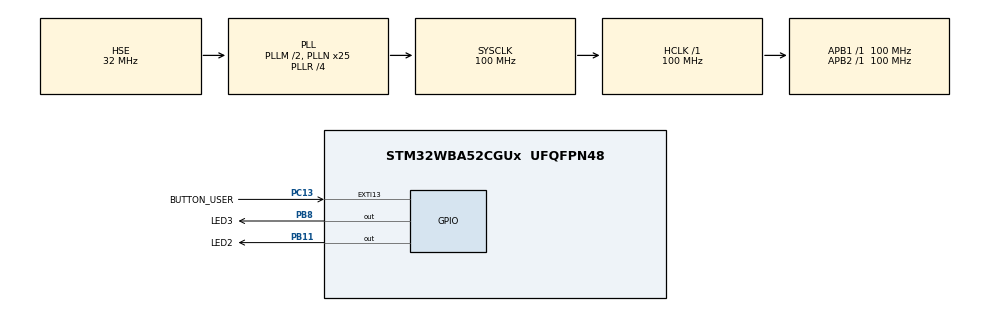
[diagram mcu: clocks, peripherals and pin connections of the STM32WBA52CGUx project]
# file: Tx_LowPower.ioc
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CORTEX_M33_NS.userName=CORTEX_M33
Mcu.Family=STM32WBA
Mcu.Name=STM32WBA52CGUx
Mcu.Package=UFQFPN48
NVIC.EXTI13_IRQn=true\:0\:0\:true\:false\:true\:false\:true\:true\:true
NVIC.PriorityGroup=NVIC_PRIORITYGROUP_4
NVIC.TIM16_IRQn=true\:15\:0\:false\:false\:true\:false\:false\:true\:true
NVIC.TimeBase=TIM16_IRQn
NVIC.TimeBaseIP=TIM16
OSC_IN.Mode=HSE-External-Oscillator
OSC_IN.Signal=RCC_OSC_IN
OSC_OUT.Mode=HSE-External-Oscillator
OSC_OUT.Signal=RCC_OSC_OUT
PB11.GPIO_Label=LED2
PB11.PinState=GPIO_PIN_SET
PB11.Signal=GPIO_Output
PB8.GPIO_Label=LED3
PB8.PinState=GPIO_PIN_SET
PB8.Signal=GPIO_Output
PC13.GPIO_Label=BUTTON_USER
PC13.GPIO_ModeDefaultEXTI=GPIO_MODE_IT_FALLING
PC13.GPIO_PuPd=GPIO_PULLUP
PC13.Signal=GPXTI13
PWR.pwrPrivilege=PWR_PRIVILEGE_NO
ProjectManager.HeapSize=0x200
ProjectManager.StackSize=0x400
ProjectManager.TargetToolchain=EWARM V9.20
RCC.ADCFreq_Value=100000000
RCC.AHB5CLKDivider=DIV4
RCC.AHBFreq_Value=100000000
RCC.APB1Freq_Value=100000000
RCC.APB1TimFreq_Value=100000000
RCC.APB2Freq_Value=100000000
RCC.APB2TimFreq_Value=100000000
RCC.CortexFreq_Value=12500000
RCC.HCLKFreq_Value=100000000
RCC.HSE_VALUE=32000000
RCC.HSI_VALUE=16000000
RCC.LSE_VALUE=32768
RCC.PLL1R=4
RCC.PLLFRACN=0
RCC.PLLM=2
RCC.PLLN=25
RCC.PLLSourceVirtual=RCC_PLLSOURCE_HSE
RCC.PREFETCH_ENABLE=0
RCC.PWR_Regulator_Voltage_Scale=PWR_REGULATOR_VOLTAGE_SCALE1
RCC.SYSCLKFreq_VALUE=100000000
RCC.SYSCLKSourceVirtual=RCC_SYSCLKSOURCE_PLLCLK
RCC.VCOOutputFreq_Value=400000000
THREADX.TX_APP_CREATION=1
THREADX.TX_APP_GENERATE_INIT_CODE=true
THREADX.TX_APP_MEM_POOL_SIZE=2 * 1024
THREADX.TX_APP_SEM_CREATION=1
THREADX.TX_APP_THREAD_ENTRY=MainThread_Entry
THREADX.TX_APP_THREAD_NAME=Main Thread
THREADX.TX_LOW_POWER=1
THREADX.TX_LOW_POWER_TICKLESS=0
THREADX.TX_LOW_POWER_TIMER_SETUP=\ 
THREADX.TX_LOW_POWER_USER_TIMER_ADJUST=\ 
THREADX.TX_SEMAPHORE_NAME=Semaphore
THREADX.TX_TIMER_THREAD_STACK_SIZE=1024
THREADX.TX_TIMER_TICKS_PER_SECOND=100
VP_ICACHE_VS_ICACHE.Mode=DirectMappedCache
VP_PWR_VS_SECSignals.Mode=Security/Privilege
VP_SYS_VS_tim16.Mode=TIM16
VP_THREADX_VS_RTOSJjThreadXJjCoreJjDefault.Mode=Core_Default
VP_THREADX_VS_RTOSJjThreadXJjLow_Power_Support.Mode=Low_Power_Support
board=NUCLEO-WBA52CG

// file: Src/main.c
/* USER CODE BEGIN Header */
/**
  ******************************************************************************
  * @file           : main.c
  * @brief          : Main program body
  ******************************************************************************
  * @attention
  *
  * Copyright (c) 2022 STMicroelectronics.
  * All rights reserved.
  *
  * This software is licensed under terms that can be found in the LICENSE file
  * in the root directory of this software component.
  * If no LICENSE file comes with this software, it is provided AS-IS.
  *
  ******************************************************************************
  */
/* USER CODE END Header */
#include "app_threadx.h"
#include "main.h"

void SystemClock_Config(void);
static void MX_GPIO_Init(void);
static void MX_ICACHE_Init(void);

int main(void)
{

  /* MCU Configuration--------------------------------------------------------*/

  /* Reset of all peripherals, Initializes the Flash interface and the Systick. */
  HAL_Init();

  /* Configure the system clock */
  SystemClock_Config();

  /* Initialize all configured peripherals */
  MX_GPIO_Init();
  MX_ICACHE_Init();

  MX_ThreadX_Init();

  /* We should never get here as control is now taken by the scheduler */
  /* Infinite loop */
  while (1)
  {

  }
}

void SystemClock_Config(void)
{
  RCC_OscInitTypeDef RCC_OscInitStruct = {0};
  RCC_ClkInitTypeDef RCC_ClkInitStruct = {0};

  /** Configure the main internal regulator output voltage
  */
  if (HAL_PWREx_ControlVoltageScaling(PWR_REGULATOR_VOLTAGE_SCALE1) != HAL_OK)
  {
    Error_Handler();
  }

  /** Initializes the CPU, AHB and APB busses clocks
  */
  RCC_OscInitStruct.OscillatorType = RCC_OSCILLATORTYPE_HSE;
  RCC_OscInitStruct.HSEState = RCC_HSE_ON;
  RCC_OscInitStruct.HSEDiv = RCC_HSE_DIV1;
  RCC_OscInitStruct.PLL1.PLLState = RCC_PLL_ON;
  RCC_OscInitStruct.PLL1.PLLSource = RCC_PLLSOURCE_HSE;
  RCC_OscInitStruct.PLL1.PLLM = 2;
  RCC_OscInitStruct.PLL1.PLLN = 25;
  RCC_OscInitStruct.PLL1.PLLP = 2;
  RCC_OscInitStruct.PLL1.PLLQ = 2;
  RCC_OscInitStruct.PLL1.PLLR = 4;
  RCC_OscInitStruct.PLL1.PLLFractional = 0;
  if (HAL_RCC_OscConfig(&RCC_OscInitStruct) != HAL_OK)
  {
    Error_Handler();
  }

  /** Initializes the CPU, AHB and APB busses clocks
  */
  RCC_ClkInitStruct.ClockType = RCC_CLOCKTYPE_HCLK|RCC_CLOCKTYPE_SYSCLK
                              |RCC_CLOCKTYPE_PCLK1|RCC_CLOCKTYPE_PCLK2
                              |RCC_CLOCKTYPE_PCLK7|RCC_CLOCKTYPE_HCLK5;
  RCC_ClkInitStruct.SYSCLKSource = RCC_SYSCLKSOURCE_PLLCLK;
  RCC_ClkInitStruct.AHBCLKDivider = RCC_SYSCLK_DIV1;
  RCC_ClkInitStruct.APB1CLKDivider = RCC_HCLK_DIV1;
  RCC_ClkInitStruct.APB2CLKDivider = RCC_HCLK_DIV1;
  RCC_ClkInitStruct.APB7CLKDivider = RCC_HCLK_DIV1;
  RCC_ClkInitStruct.AHB5_PLL1_CLKDivider = RCC_SYSCLK_PLL1_DIV4;
  RCC_ClkInitStruct.AHB5_HSEHSI_CLKDivider = RCC_SYSCLK_HSEHSI_DIV1;

  if (HAL_RCC_ClockConfig(&RCC_ClkInitStruct, FLASH_LATENCY_3) != HAL_OK)
  {
    Error_Handler();
  }
}

static void MX_ICACHE_Init(void)
{

  /** Enable instruction cache in 1-way (direct mapped cache)
  */
  if (HAL_ICACHE_ConfigAssociativityMode(ICACHE_1WAY) != HAL_OK)
  {
    Error_Handler();
  }
  if (HAL_ICACHE_Enable() != HAL_OK)
  {
    Error_Handler();
  }

}

static void MX_GPIO_Init(void)
{
  GPIO_InitTypeDef GPIO_InitStruct = {0};

  /* GPIO Ports Clock Enable */
  __HAL_RCC_GPIOB_CLK_ENABLE();
  __HAL_RCC_GPIOA_CLK_ENABLE();
  __HAL_RCC_GPIOC_CLK_ENABLE();
  __HAL_RCC_GPIOH_CLK_ENABLE();

  /*Configure GPIO pin Output Level */
  HAL_GPIO_WritePin(GPIOB, LED2_Pin|LED3_Pin, GPIO_PIN_SET);

  /*Configure GPIO pins : PB12 PB10 PB9 PB7
                           PB6 PB5 PB4 PB3
                           PB2 PB1 PB0 PB15
                           PB14 PB13 */
  GPIO_InitStruct.Pin = GPIO_PIN_12|GPIO_PIN_10|GPIO_PIN_9|GPIO_PIN_7
                          |GPIO_PIN_6|GPIO_PIN_5|GPIO_PIN_4|GPIO_PIN_3
                          |GPIO_PIN_2|GPIO_PIN_1|GPIO_PIN_0|GPIO_PIN_15
                          |GPIO_PIN_14|GPIO_PIN_13;
  GPIO_InitStruct.Mode = GPIO_MODE_ANALOG;
  GPIO_InitStruct.Pull = GPIO_NOPULL;
  HAL_GPIO_Init(GPIOB, &GPIO_InitStruct);

  /*Configure GPIO pins : LED2_Pin LED3_Pin */
  GPIO_InitStruct.Pin = LED2_Pin|LED3_Pin;
  GPIO_InitStruct.Mode = GPIO_MODE_OUTPUT_PP;
  GPIO_InitStruct.Pull = GPIO_NOPULL;
  GPIO_InitStruct.Speed = GPIO_SPEED_FREQ_LOW;
  HAL_GPIO_Init(GPIOB, &GPIO_InitStruct);

  /*Configure GPIO pins : PA8 PA7 PA6 PA5
                           PA3 PA2 PA1 PA0
                           PA15 PA14 PA13 PA12
                           PA11 PA10 PA9 */
  GPIO_InitStruct.Pin = GPIO_PIN_8|GPIO_PIN_7|GPIO_PIN_6|GPIO_PIN_5
                          |GPIO_PIN_3|GPIO_PIN_2|GPIO_PIN_1|GPIO_PIN_0
                          |GPIO_PIN_15|GPIO_PIN_14|GPIO_PIN_13|GPIO_PIN_12
                          |GPIO_PIN_11|GPIO_PIN_10|GPIO_PIN_9;
  GPIO_InitStruct.Mode = GPIO_MODE_ANALOG;
  GPIO_InitStruct.Pull = GPIO_NOPULL;
  HAL_GPIO_Init(GPIOA, &GPIO_InitStruct);

  /*Configure GPIO pins : PC15 PC14 */
  GPIO_InitStruct.Pin = GPIO_PIN_15|GPIO_PIN_14;
  GPIO_InitStruct.Mode = GPIO_MODE_ANALOG;
  GPIO_InitStruct.Pull = GPIO_NOPULL;
  HAL_GPIO_Init(GPIOC, &GPIO_InitStruct);

  /*Configure GPIO pin : BUTTON_USER_Pin */
  GPIO_InitStruct.Pin = BUTTON_USER_Pin;
  GPIO_InitStruct.Mode = GPIO_MODE_IT_FALLING;
  GPIO_InitStruct.Pull = GPIO_PULLUP;
  HAL_GPIO_Init(BUTTON_USER_GPIO_Port, &GPIO_InitStruct);

  /*Configure GPIO pin : PH3 */
  GPIO_InitStruct.Pin = GPIO_PIN_3;
  GPIO_InitStruct.Mode = GPIO_MODE_ANALOG;
  GPIO_InitStruct.Pull = GPIO_NOPULL;
  HAL_GPIO_Init(GPIOH, &GPIO_InitStruct);

  /* EXTI interrupt init*/
  HAL_NVIC_SetPriority(EXTI13_IRQn, 0, 0);
  HAL_NVIC_EnableIRQ(EXTI13_IRQn);

}

void HAL_TIM_PeriodElapsedCallback(TIM_HandleTypeDef *htim)
{
  if (htim->Instance == TIM16) {
    HAL_IncTick();
  }
}

void Error_Handler(void)
{
  /* USER CODE BEGIN Error_Handler_Debug */
  /* User can add his own implementation to report the HAL error return state */
  HAL_GPIO_WritePin(LED2_GPIO_Port, LED2_Pin, GPIO_PIN_SET);
  while (1)
  {
    HAL_GPIO_TogglePin(LED3_GPIO_Port, LED3_Pin);
    HAL_Delay(1000);
  }
  /* USER CODE END Error_Handler_Debug */
}
